# NUC123BN_v1 register map
File version: 1.0
Registers are 32-bit, read-write, reset 0x0 unless marked. A register's access mark holds for its fields unless they carry their own. Offsets are from the block's base; [hi:lo] are bit positions.

## PDMA_ch0 — PDMA Register Map
Base 0x50008000
Same registers: PDMA_ch1 0x50008100, PDMA_ch2 0x50008200, PDMA_ch3 0x50008300, PDMA_ch4 0x50008400, PDMA_ch5 0x50008500
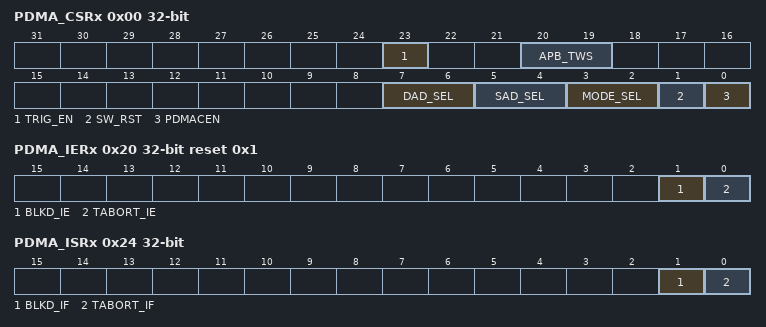
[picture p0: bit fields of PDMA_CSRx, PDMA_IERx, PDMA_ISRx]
0x00 PDMA_CSRx — PDMA Control and Status Register
  [23] TRIG_EN — TRIG_EN. Note: When PDMA transfer completed, this bit will be cleared automatically. If the bus error occurs, all PDMA transfer will be stopped. Software must reset all PDMA channel, and then trigger again.
    0=No effect; 1=PDMA data read or write transfer Enabled
  [20:19] APB_TWS — Peripheral Transfer Width Selection. Note: This field is meaningful only when MODE_SEL is Peripheral to Memory mode (Peripheral-to-Memory) or Memory to Peripheral mode (Memory-to-Peripheral).
    0=One word (32-bit) is transferred for every PDMA operation; 1=One byte (8-bit) is transferred for every PDMA operation; 2=One half-word (16-bit) is transferred for every PDMA operation
  [7:6] DAD_SEL — Transfer Destination Address Direction Selection
    0=Transfer destination address is increasing successively; 2=Transfer destination address is fixed (This feature can be used when data transferred from multiple sources to a single destination)
  [5:4] SAD_SEL — Transfer Source Address Direction Selection
    0=Transfer source address is increasing successively; 2=Transfer source address is fixed (This feature can be used when data where transferred from a single source to multiple destinations)
  [3:2] MODE_SEL — PDMA Mode Selection
    0=Memory to Memory mode (Memory-to-Memory); 1=Peripheral to Memory mode (Peripheral-to-Memory); 2=Memory to Peripheral mode (Memory-to-Peripheral)
  [1] SW_RST — Software Engine Reset
    0=No effect; 1=Reset the internal state machine, pointers and internal buffer. The contents of control register will not be cleared. This bit will be automatically cleared after few clock cycles
  [0] PDMACEN — PDMA Channel Enable. Setting this bit to 1 enables PDMA's operation. If this bit is cleared, PDMA will ignore all PDMA request and force Bus Master into IDLE state.
0x04 PDMA_SARx — PDMA Transfer Source Address Register
  [31:0] PDMA_SAR — PDMA Transfer Source Address Register. This field indicates a 32-bit source address of PDMA. Note: The source address must be word alignment.
0x08 PDMA_DARx — PDMA Transfer Destination Address Register
  [31:0] PDMA_DAR — PDMA Transfer Destination Address Register. This field indicates a 32-bit destination address of PDMA. Note: The destination address must be word alignment.
0x0C PDMA_BCRx — PDMA Transfer Byte Count Register
  [15:0] PDMA_BCR — PDMA Transfer Byte Count Register. This field indicates a 16-bit transfer byte count number of PDMA; it must be word alignment.
0x10 PDMA_POINTx ro — PDMA Internal Buffer Pointer Register
  [1:0] PDMA_POINT — PDMA Internal Buffer Pointer Register (Read Only). This field indicates the internal buffer pointer.
0x14 PDMA_CSARx ro — PDMA Current Source Address Register
  [31:0] PDMA_CSAR — PDMA Current Source Address Register (Read Only). This field indicates the source address where the PDMA transfer just occurs.
0x18 PDMA_CDARx ro — PDMA Current Destination Address Register
  [31:0] PDMA_CDAR — PDMA Current Destination Address Register (Read Only). This field indicates the destination address where the PDMA transfer just occurs.
0x1C PDMA_CBCRx ro — PDMA Current Byte Count Register
  [15:0] PDMA_CBCR — PDMA Current Byte Count Register (Read Only). This field indicates the current remained byte count of PDMA. Note: SW_RST will clear this register value.
0x20 PDMA_IERx reset 0x1 — PDMA Interrupt Enable Control Register
  [1] BLKD_IE — PDMA Transfer Done Interrupt Enable
    0=Interrupt generator Disabled when PDMA transfer is done; 1=Interrupt generator Enabled when PDMA transfer is done
  [0] TABORT_IE — PDMA Read/Write Target Abort Interrupt Enable
    0=Target abort interrupt generation Disabled during PDMA transfer; 1=Target abort interrupt generation Enabled during PDMA transfer
0x24 PDMA_ISRx — PDMA Interrupt Status Register
  [1] BLKD_IF — Block Transfer Done Interrupt Flag. This bit indicates that PDMA has finished all transfer. Software can write 1 to clear this bit to zero.
    0=Not finished; 1=Done
  [0] TABORT_IF — PDMA Read/Write Target Abort Interrupt Flag. Software can write 1 to clear this bit to zero.
    0=No bus ERROR response received; 1=Bus ERROR response received
0x80 PDMA_SBUF_cx ro — PDMA Shared Buffer FIFO
  [31:0] PDMA_SBUF — PDMA Shared Buffer FIFO (Read Only). Each channel has its own 1 word internal buffer.
